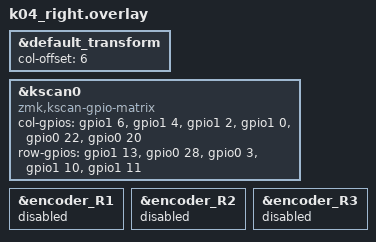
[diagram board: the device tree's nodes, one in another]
#include "k04.dtsi"

&default_transform {
    col-offset = <6>;
};

&kscan0 {
    compatible = "zmk,kscan-gpio-matrix";

    col-gpios
        = <&gpio1  6 GPIO_ACTIVE_HIGH>
        , <&gpio1  4 GPIO_ACTIVE_HIGH>
        , <&gpio1  2 GPIO_ACTIVE_HIGH>
        , <&gpio1  0 GPIO_ACTIVE_HIGH>
        , <&gpio0 22 GPIO_ACTIVE_HIGH>
        , <&gpio0 20 GPIO_ACTIVE_HIGH>
        ;

    row-gpios
        = <&gpio1 13 (GPIO_ACTIVE_HIGH | GPIO_PULL_DOWN)>
        , <&gpio0 28 (GPIO_ACTIVE_HIGH | GPIO_PULL_DOWN)>
        , <&gpio0  3 (GPIO_ACTIVE_HIGH | GPIO_PULL_DOWN)>
        , <&gpio1 10 (GPIO_ACTIVE_HIGH | GPIO_PULL_DOWN)>
        , <&gpio1 11 (GPIO_ACTIVE_HIGH | GPIO_PULL_DOWN)>
        // , <&gpio0 15 (GPIO_ACTIVE_HIGH | GPIO_PULL_DOWN)>
        ;
};

&encoder_R1 {
    status = "disabled";
};

&encoder_R2 {
    status = "disabled";
};

&encoder_R3 {
    status = "disabled";
};
